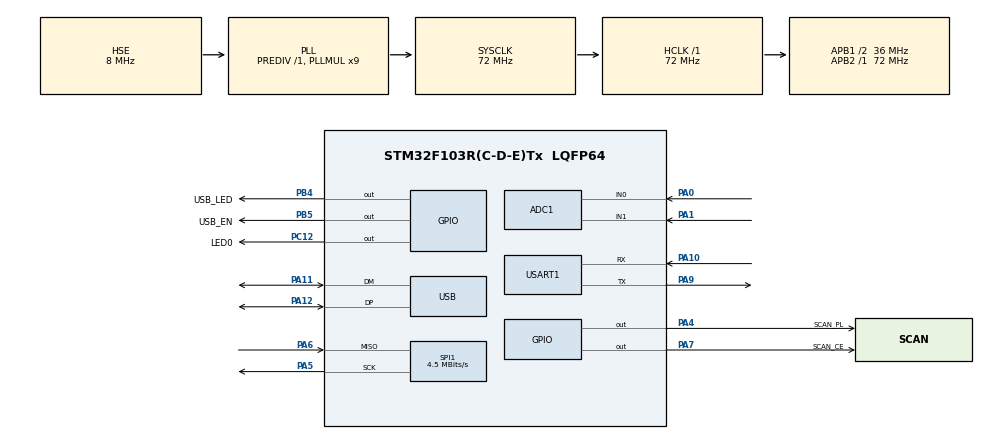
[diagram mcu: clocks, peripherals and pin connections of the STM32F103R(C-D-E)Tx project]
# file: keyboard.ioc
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ADC1.Channel-0\#ChannelRegularConversion=ADC_CHANNEL_0
ADC1.Channel-1\#ChannelRegularConversion=ADC_CHANNEL_1
ADC1.ContinuousConvMode=ENABLE
ADC1.DiscontinuousConvMode=DISABLE
ADC1.NbrOfConversion=2
ADC1.NbrOfConversionFlag=1
ADC1.Rank-0\#ChannelRegularConversion=1
ADC1.Rank-1\#ChannelRegularConversion=2
ADC1.SamplingTime-0\#ChannelRegularConversion=ADC_SAMPLETIME_1CYCLE_5
ADC1.SamplingTime-1\#ChannelRegularConversion=ADC_SAMPLETIME_1CYCLE_5
ADC1.master=1
Dma.ADC1.2.Direction=DMA_PERIPH_TO_MEMORY
Dma.ADC1.2.Instance=DMA1_Channel1
Dma.ADC1.2.MemDataAlignment=DMA_MDATAALIGN_HALFWORD
Dma.ADC1.2.MemInc=DMA_MINC_ENABLE
Dma.ADC1.2.Mode=DMA_CIRCULAR
Dma.ADC1.2.PeriphDataAlignment=DMA_PDATAALIGN_HALFWORD
Dma.ADC1.2.PeriphInc=DMA_PINC_DISABLE
Dma.ADC1.2.Priority=DMA_PRIORITY_MEDIUM
Dma.Request0=USART1_RX
Dma.Request1=USART1_TX
Dma.Request2=ADC1
Dma.USART1_RX.0.Direction=DMA_PERIPH_TO_MEMORY
Dma.USART1_RX.0.Instance=DMA1_Channel5
Dma.USART1_RX.0.MemDataAlignment=DMA_MDATAALIGN_BYTE
Dma.USART1_RX.0.MemInc=DMA_MINC_ENABLE
Dma.USART1_RX.0.Mode=DMA_NORMAL
Dma.USART1_RX.0.PeriphDataAlignment=DMA_PDATAALIGN_BYTE
Dma.USART1_RX.0.PeriphInc=DMA_PINC_DISABLE
Dma.USART1_RX.0.Priority=DMA_PRIORITY_LOW
Dma.USART1_TX.1.Direction=DMA_MEMORY_TO_PERIPH
Dma.USART1_TX.1.Instance=DMA1_Channel4
Dma.USART1_TX.1.MemDataAlignment=DMA_MDATAALIGN_BYTE
Dma.USART1_TX.1.MemInc=DMA_MINC_ENABLE
Dma.USART1_TX.1.Mode=DMA_NORMAL
Dma.USART1_TX.1.PeriphDataAlignment=DMA_PDATAALIGN_BYTE
Dma.USART1_TX.1.PeriphInc=DMA_PINC_DISABLE
Dma.USART1_TX.1.Priority=DMA_PRIORITY_LOW
Mcu.Family=STM32F1
Mcu.Name=STM32F103R(C-D-E)Tx
Mcu.Package=LQFP64
NVIC.DMA1_Channel1_IRQn=true\:0\:0\:false\:false\:true\:false\:true\:true
NVIC.DMA1_Channel4_IRQn=true\:0\:0\:false\:false\:true\:false\:true\:true
NVIC.DMA1_Channel5_IRQn=true\:0\:0\:false\:false\:true\:false\:true\:true
NVIC.PriorityGroup=NVIC_PRIORITYGROUP_4
NVIC.USART1_IRQn=true\:0\:0\:false\:false\:true\:true\:true\:true
NVIC.USB_LP_CAN1_RX0_IRQn=true\:0\:0\:false\:false\:true\:false\:true\:true
PA0-WKUP.Signal=ADCx_IN0
PA1.Signal=ADCx_IN1
PA10.Mode=Asynchronous
PA10.Signal=USART1_RX
PA11.Mode=Device
PA11.Signal=USB_DM
PA12.Mode=Device
PA12.Signal=USB_DP
PA13.Mode=Serial_Wire
PA13.Signal=SYS_JTMS-SWDIO
PA14.Mode=Serial_Wire
PA14.Signal=SYS_JTCK-SWCLK
PA4.GPIO_Label=SCAN_PL
PA4.GPIO_PuPd=GPIO_NOPULL
PA4.GPIO_Speed=GPIO_SPEED_FREQ_LOW
PA4.Signal=GPIO_Output
PA5.Mode=RX_Only_Simplex_Unidirect_Master
PA5.Signal=SPI1_SCK
PA6.Mode=RX_Only_Simplex_Unidirect_Master
PA6.Signal=SPI1_MISO
PA7.GPIO_Label=SCAN_CE
PA7.GPIO_PuPd=GPIO_NOPULL
PA7.GPIO_Speed=GPIO_SPEED_FREQ_LOW
PA7.Signal=GPIO_Output
PA9.Mode=Asynchronous
PA9.Signal=USART1_TX
PB4.GPIO_Label=USB_LED
PB4.GPIO_PuPd=GPIO_PULLUP
PB4.Signal=GPIO_Output
PB5.GPIO_Label=USB_EN
PB5.GPIO_PuPd=GPIO_PULLDOWN
PB5.Signal=GPIO_Output
PC12.GPIO_Label=LED0
PC12.GPIO_PuPd=GPIO_PULLUP
PC12.Signal=GPIO_Output
PD0-OSC_IN.Mode=HSE-External-Oscillator
PD0-OSC_IN.Signal=RCC_OSC_IN
PD1-OSC_OUT.Mode=HSE-External-Oscillator
PD1-OSC_OUT.Signal=RCC_OSC_OUT
ProjectManager.HeapSize=0x600
ProjectManager.StackSize=0x400
ProjectManager.TargetToolchain=STM32CubeIDE
RCC.ADCPresc=RCC_ADCPCLK2_DIV6
RCC.AHBFreq_Value=72000000
RCC.APB1CLKDivider=RCC_HCLK_DIV2
RCC.APB1Freq_Value=36000000
RCC.APB1TimFreq_Value=72000000
RCC.APB2Freq_Value=72000000
RCC.APB2TimFreq_Value=72000000
RCC.HCLKFreq_Value=72000000
RCC.PLLMUL=RCC_PLL_MUL9
RCC.SYSCLKFreq_VALUE=72000000
RCC.SYSCLKSource=RCC_SYSCLKSOURCE_PLLCLK
RCC.USBFreq_Value=48000000
RCC.USBPrescaler=RCC_USBCLKSOURCE_PLL_DIV1_5
SH.ADCx_IN0.0=ADC1_IN0,IN0
SH.ADCx_IN1.0=ADC1_IN1,IN1
SPI1.BaudRatePrescaler=SPI_BAUDRATEPRESCALER_16
SPI1.CLKPolarity=SPI_POLARITY_HIGH
SPI1.CRCCalculation=SPI_CRCCALCULATION_DISABLE
SPI1.CalculateBaudRate=4.5 MBits/s
SPI1.Direction=SPI_DIRECTION_2LINES_RXONLY
SPI1.FirstBit=SPI_FIRSTBIT_LSB
SPI1.Mode=SPI_MODE_MASTER
SPI1.VirtualType=VM_MASTER
USART1.VirtualMode=VM_ASYNC
USB_DEVICE.CLASS_NAME_FS=CUSTOM_HID
USB_DEVICE.CUSTOM_HID_FS_BINTERVAL=0xA
USB_DEVICE.PID_CUSTOMHID_FS=20310
USB_DEVICE.USBD_CUSTOMHID_OUTREPORT_BUF_SIZE=64
USB_DEVICE.USBD_CUSTOM_HID_REPORT_DESC_SIZE=57
USB_DEVICE.USBD_MAX_NUM_INTERFACES=1
USB_DEVICE.USBD_SELF_POWERED=0
USB_DEVICE.VID=1020
USB_DEVICE.VirtualMode=CustomHid
USB_DEVICE.VirtualModeFS=Custom_Hid_FS
VP_USB_DEVICE_VS_USB_DEVICE_CUSTOM_HID_FS.Mode=CUSTOM_HID_FS
board=custom

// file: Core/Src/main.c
/* USER CODE BEGIN Header */
/**
  ******************************************************************************
  * @file           : main.c
  * @brief          : Main program body
  ******************************************************************************
  * @attention
  *
  * Copyright (c) 2024 STMicroelectronics.
  * All rights reserved.
  *
  * This software is licensed under terms that can be found in the LICENSE file
  * in the root directory of this software component.
  * If no LICENSE file comes with this software, it is provided AS-IS.
  *
  ******************************************************************************
  */
/* USER CODE END Header */
#include "main.h"
#include "adc.h"
#include "dma.h"
#include "spi.h"
#include "usart.h"
#include "usb_device.h"
#include "gpio.h"

/* USER CODE BEGIN Includes */
#include "../../Drivers/BSP/RF_keyboard.h"

/* USER CODE END Includes */

void SystemClock_Config(void);

int main(void)
{

  /* MCU Configuration--------------------------------------------------------*/

  /* Reset of all peripherals, Initializes the Flash interface and the Systick. */
  HAL_Init();

  /* Configure the system clock */
  SystemClock_Config();

  /* Initialize all configured peripherals */
  MX_GPIO_Init();
  MX_DMA_Init();
  MX_USART1_UART_Init();
  MX_USB_DEVICE_Init();
  MX_ADC1_Init();
  MX_SPI1_Init();
  /* USER CODE BEGIN 2 */
  RFK_init();
  uart1_init();
  HAL_ADCEx_Calibration_Start(&hadc1);
  HAL_ADC_Start_DMA(&hadc1,(uint32_t*)(RFK.joy_value_arr),200);
  uart1_report("init done\r\n");
  HAL_GPIO_WritePin(SCAN_CE_GPIO_Port, SCAN_CE_Pin, GPIO_PIN_RESET);
  HAL_GPIO_TogglePin(USB_EN_GPIO_Port, USB_EN_Pin);
//    __HAL_SPI_ENABLE(RFK.spiHandle);
  /* USER CODE END 2 */

  /* Infinite loop */
  /* USER CODE BEGIN WHILE */
  while (1)
  {
    RFK.scanKeyboard();
    RFK.buildHidBuffer();
    RFK.reportHid();
    HAL_GPIO_TogglePin(LED0_GPIO_Port, LED0_Pin);
//    uart1_report("get:[%d, %d, %d, %d]\r\n",
//                 RFK.mapBuffer[0], RFK.mapBuffer[1], RFK.mapBuffer[2], RFK.mapBuffer[3]);
    HAL_Delay(10);
    /* USER CODE END WHILE */

  }
}

void SystemClock_Config(void)
{
  RCC_OscInitTypeDef RCC_OscInitStruct = {0};
  RCC_ClkInitTypeDef RCC_ClkInitStruct = {0};
  RCC_PeriphCLKInitTypeDef PeriphClkInit = {0};

  /** Initializes the RCC Oscillators according to the specified parameters
  * in the RCC_OscInitTypeDef structure.
  */
  RCC_OscInitStruct.OscillatorType = RCC_OSCILLATORTYPE_HSE;
  RCC_OscInitStruct.HSEState = RCC_HSE_ON;
  RCC_OscInitStruct.HSEPredivValue = RCC_HSE_PREDIV_DIV1;
  RCC_OscInitStruct.HSIState = RCC_HSI_ON;
  RCC_OscInitStruct.PLL.PLLState = RCC_PLL_ON;
  RCC_OscInitStruct.PLL.PLLSource = RCC_PLLSOURCE_HSE;
  RCC_OscInitStruct.PLL.PLLMUL = RCC_PLL_MUL9;
  if (HAL_RCC_OscConfig(&RCC_OscInitStruct) != HAL_OK)
  {
    Error_Handler();
  }

  /** Initializes the CPU, AHB and APB buses clocks
  */
  RCC_ClkInitStruct.ClockType = RCC_CLOCKTYPE_HCLK|RCC_CLOCKTYPE_SYSCLK
                              |RCC_CLOCKTYPE_PCLK1|RCC_CLOCKTYPE_PCLK2;
  RCC_ClkInitStruct.SYSCLKSource = RCC_SYSCLKSOURCE_PLLCLK;
  RCC_ClkInitStruct.AHBCLKDivider = RCC_SYSCLK_DIV1;
  RCC_ClkInitStruct.APB1CLKDivider = RCC_HCLK_DIV2;
  RCC_ClkInitStruct.APB2CLKDivider = RCC_HCLK_DIV1;

  if (HAL_RCC_ClockConfig(&RCC_ClkInitStruct, FLASH_LATENCY_2) != HAL_OK)
  {
    Error_Handler();
  }
  PeriphClkInit.PeriphClockSelection = RCC_PERIPHCLK_ADC|RCC_PERIPHCLK_USB;
  PeriphClkInit.AdcClockSelection = RCC_ADCPCLK2_DIV6;
  PeriphClkInit.UsbClockSelection = RCC_USBCLKSOURCE_PLL_DIV1_5;
  if (HAL_RCCEx_PeriphCLKConfig(&PeriphClkInit) != HAL_OK)
  {
    Error_Handler();
  }
}

void Error_Handler(void)
{
  __disable_irq();
  while (1)
  {
  }
}
